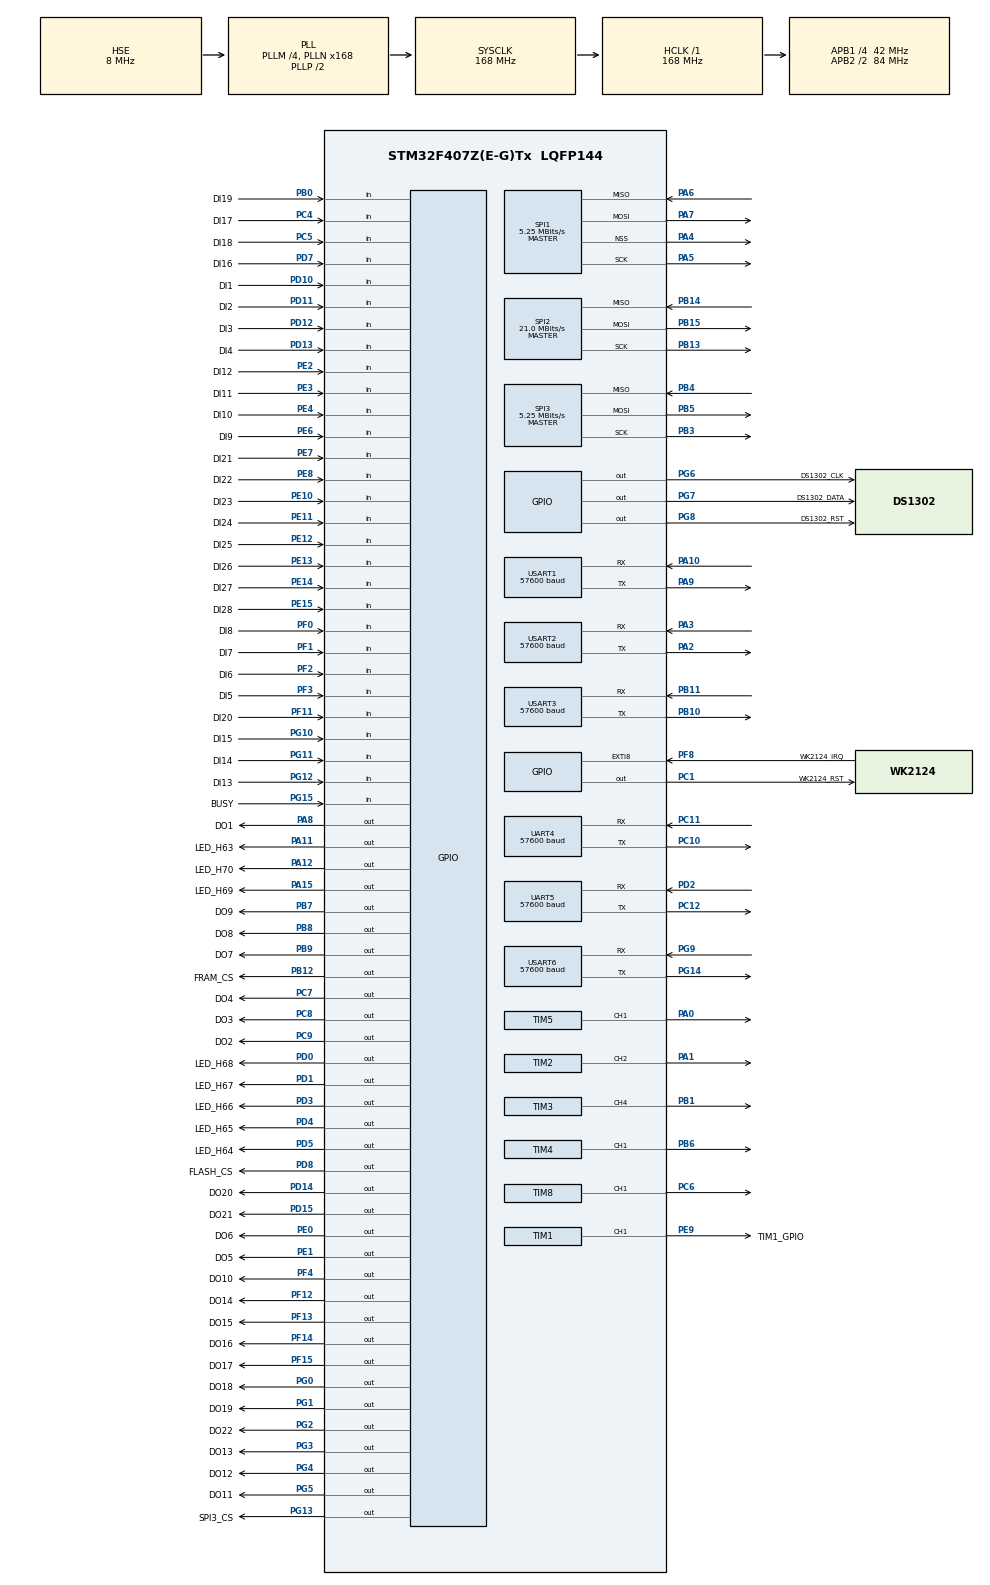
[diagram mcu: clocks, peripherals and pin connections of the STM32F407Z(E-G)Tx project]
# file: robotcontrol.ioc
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Mcu.Family=STM32F4
Mcu.Name=STM32F407Z(E-G)Tx
Mcu.Package=LQFP144
NVIC.EXTI9_5_IRQn=true\:0\:0\:false\:false\:true\:true\:true
NVIC.PriorityGroup=NVIC_PRIORITYGROUP_2
NVIC.TIM1_UP_TIM10_IRQn=true\:0\:0\:false\:false\:true\:true\:true
NVIC.TIM2_IRQn=true\:0\:0\:false\:false\:true\:true\:true
NVIC.TIM3_IRQn=true\:0\:0\:false\:false\:true\:true\:true
NVIC.TIM4_IRQn=true\:0\:0\:false\:false\:true\:true\:true
NVIC.TIM5_IRQn=true\:0\:0\:false\:false\:true\:true\:true
NVIC.TIM6_DAC_IRQn=true\:0\:0\:false\:false\:true\:true\:true
NVIC.TIM8_UP_TIM13_IRQn=true\:0\:0\:false\:false\:true\:true\:true
NVIC.UART4_IRQn=true\:0\:0\:false\:false\:true\:true\:true
NVIC.UART5_IRQn=true\:0\:0\:false\:false\:true\:true\:true
NVIC.USART1_IRQn=true\:0\:0\:false\:false\:true\:true\:true
NVIC.USART2_IRQn=true\:0\:0\:false\:false\:true\:true\:true
NVIC.USART3_IRQn=true\:0\:0\:false\:false\:true\:true\:true
NVIC.USART6_IRQn=true\:0\:0\:false\:false\:true\:true\:true
PA0-WKUP.Signal=S_TIM5_CH1
PA1.GPIO_PuPd=GPIO_PULLUP
PA1.GPIO_Speed=GPIO_SPEED_FREQ_MEDIUM
PA1.Signal=S_TIM2_CH2
PA10.GPIO_Speed=GPIO_SPEED_FREQ_MEDIUM
PA10.Mode=Asynchronous
PA10.Signal=USART1_RX
PA11.GPIO_Label=LED_H63
PA11.GPIO_PuPd=GPIO_PULLUP
PA11.PinState=GPIO_PIN_SET
PA11.Signal=GPIO_Output
PA12.GPIO_Label=LED_H70
PA12.GPIO_PuPd=GPIO_PULLUP
PA12.PinState=GPIO_PIN_SET
PA12.Signal=GPIO_Output
PA13.Mode=Serial_Wire
PA13.Signal=SYS_JTMS-SWDIO
PA14.Mode=Serial_Wire
PA14.Signal=SYS_JTCK-SWCLK
PA15.GPIO_Label=LED_H69
PA15.GPIO_PuPd=GPIO_PULLUP
PA15.PinState=GPIO_PIN_SET
PA15.Signal=GPIO_Output
PA2.GPIO_Speed=GPIO_SPEED_FREQ_MEDIUM
PA2.Mode=Asynchronous
PA2.Signal=USART2_TX
PA3.GPIO_Speed=GPIO_SPEED_FREQ_MEDIUM
PA3.Mode=Asynchronous
PA3.Signal=USART2_RX
PA4.Mode=NSS_Signal_Hard_Output
PA4.Signal=SPI1_NSS
PA5.Mode=Full_Duplex_Master
PA5.Signal=SPI1_SCK
PA6.Mode=Full_Duplex_Master
PA6.Signal=SPI1_MISO
PA7.Mode=Full_Duplex_Master
PA7.Signal=SPI1_MOSI
PA8.GPIO_Label=DO1
PA8.GPIO_PuPd=GPIO_PULLUP
PA8.GPIO_Speed=GPIO_SPEED_FREQ_LOW
PA8.PinState=GPIO_PIN_SET
PA8.Signal=GPIO_Output
PA9.GPIO_Speed=GPIO_SPEED_FREQ_MEDIUM
PA9.Mode=Asynchronous
PA9.Signal=USART1_TX
PB0.GPIO_Label=DI19
PB0.GPIO_PuPd=GPIO_PULLDOWN
PB0.Signal=GPIO_Input
PB1.GPIO_PuPd=GPIO_PULLUP
PB1.GPIO_Speed=GPIO_SPEED_FREQ_MEDIUM
PB1.Signal=S_TIM3_CH4
PB10.GPIO_Speed=GPIO_SPEED_FREQ_MEDIUM
PB10.Mode=Asynchronous
PB10.Signal=USART3_TX
PB11.GPIO_Speed=GPIO_SPEED_FREQ_MEDIUM
PB11.Mode=Asynchronous
PB11.Signal=USART3_RX
PB12.GPIO_Label=FRAM_CS
PB12.GPIO_PuPd=GPIO_PULLUP
PB12.GPIO_Speed=GPIO_SPEED_FREQ_HIGH
PB12.PinState=GPIO_PIN_SET
PB12.Signal=GPIO_Output
PB13.GPIO_Speed=GPIO_SPEED_FREQ_HIGH
PB13.Mode=Full_Duplex_Master
PB13.Signal=SPI2_SCK
PB14.GPIO_Speed=GPIO_SPEED_FREQ_HIGH
PB14.Mode=Full_Duplex_Master
PB14.Signal=SPI2_MISO
PB15.GPIO_Speed=GPIO_SPEED_FREQ_HIGH
PB15.Mode=Full_Duplex_Master
PB15.Signal=SPI2_MOSI
PB3.Mode=Full_Duplex_Master
PB3.Signal=SPI3_SCK
PB4.Mode=Full_Duplex_Master
PB4.Signal=SPI3_MISO
PB5.Mode=Full_Duplex_Master
PB5.Signal=SPI3_MOSI
PB6.GPIO_PuPd=GPIO_PULLUP
PB6.GPIO_Speed=GPIO_SPEED_FREQ_MEDIUM
PB6.Signal=S_TIM4_CH1
PB7.GPIO_Label=DO9
PB7.GPIO_PuPd=GPIO_PULLUP
PB7.PinState=GPIO_PIN_SET
PB7.Signal=GPIO_Output
PB8.GPIO_Label=DO8
PB8.GPIO_PuPd=GPIO_PULLUP
PB8.PinState=GPIO_PIN_SET
PB8.Signal=GPIO_Output
PB9.GPIO_Label=DO7
PB9.GPIO_PuPd=GPIO_PULLUP
PB9.PinState=GPIO_PIN_SET
PB9.Signal=GPIO_Output
PC1.GPIO_Label=WK2124_RST
PC1.GPIO_PuPd=GPIO_PULLUP
PC1.PinState=GPIO_PIN_SET
PC1.Signal=GPIO_Output
PC10.GPIO_Speed=GPIO_SPEED_FREQ_MEDIUM
PC10.Mode=Asynchronous
PC10.Signal=UART4_TX
PC11.GPIO_Speed=GPIO_SPEED_FREQ_MEDIUM
PC11.Mode=Asynchronous
PC11.Signal=UART4_RX
PC12.GPIO_Speed=GPIO_SPEED_FREQ_MEDIUM
PC12.Mode=Asynchronous
PC12.Signal=UART5_TX
PC14-OSC32_IN.Mode=LSE-External-Oscillator
PC14-OSC32_IN.Signal=RCC_OSC32_IN
PC15-OSC32_OUT.Mode=LSE-External-Oscillator
PC15-OSC32_OUT.Signal=RCC_OSC32_OUT
PC4.GPIO_Label=DI17
PC4.GPIO_PuPd=GPIO_PULLDOWN
PC4.Signal=GPIO_Input
PC5.GPIO_Label=DI18
PC5.GPIO_PuPd=GPIO_PULLDOWN
PC5.Signal=GPIO_Input
PC6.GPIO_PuPd=GPIO_PULLUP
PC6.GPIO_Speed=GPIO_SPEED_FREQ_MEDIUM
PC6.Signal=S_TIM8_CH1
PC7.GPIO_Label=DO4
PC7.GPIO_PuPd=GPIO_PULLUP
PC7.PinState=GPIO_PIN_SET
PC7.Signal=GPIO_Output
PC8.GPIO_Label=DO3
PC8.GPIO_PuPd=GPIO_PULLUP
PC8.PinState=GPIO_PIN_SET
PC8.Signal=GPIO_Output
PC9.GPIO_Label=DO2
PC9.GPIO_PuPd=GPIO_PULLUP
PC9.PinState=GPIO_PIN_SET
PC9.Signal=GPIO_Output
PD0.GPIO_Label=LED_H68
PD0.GPIO_PuPd=GPIO_PULLUP
PD0.PinState=GPIO_PIN_SET
PD0.Signal=GPIO_Output
PD1.GPIO_Label=LED_H67
PD1.GPIO_PuPd=GPIO_PULLUP
PD1.PinState=GPIO_PIN_SET
PD1.Signal=GPIO_Output
PD10.GPIO_Label=DI1
PD10.GPIO_PuPd=GPIO_PULLDOWN
PD10.Signal=GPIO_Input
PD11.GPIO_Label=DI2
PD11.GPIO_PuPd=GPIO_PULLDOWN
PD11.Signal=GPIO_Input
PD12.GPIO_Label=DI3
PD12.GPIO_PuPd=GPIO_PULLDOWN
PD12.Signal=GPIO_Input
PD13.GPIO_Label=DI4
PD13.GPIO_PuPd=GPIO_PULLDOWN
PD13.Signal=GPIO_Input
PD14.GPIO_Label=DO20
PD14.GPIO_PuPd=GPIO_PULLUP
PD14.PinState=GPIO_PIN_SET
PD14.Signal=GPIO_Output
PD15.GPIO_Label=DO21
PD15.GPIO_PuPd=GPIO_PULLUP
PD15.PinState=GPIO_PIN_SET
PD15.Signal=GPIO_Output
PD2.GPIO_Speed=GPIO_SPEED_FREQ_MEDIUM
PD2.Mode=Asynchronous
PD2.Signal=UART5_RX
PD3.GPIO_Label=LED_H66
PD3.GPIO_PuPd=GPIO_PULLUP
PD3.PinState=GPIO_PIN_SET
PD3.Signal=GPIO_Output
PD4.GPIO_Label=LED_H65
PD4.GPIO_PuPd=GPIO_PULLUP
PD4.PinState=GPIO_PIN_SET
PD4.Signal=GPIO_Output
PD5.GPIO_Label=LED_H64
PD5.GPIO_PuPd=GPIO_PULLUP
PD5.PinState=GPIO_PIN_SET
PD5.Signal=GPIO_Output
PD7.GPIO_Label=DI16
PD7.GPIO_PuPd=GPIO_PULLDOWN
PD7.Signal=GPIO_Input
PD8.GPIO_Label=FLASH_CS
PD8.GPIO_PuPd=GPIO_PULLUP
PD8.GPIO_Speed=GPIO_SPEED_FREQ_HIGH
PD8.PinState=GPIO_PIN_SET
PD8.Signal=GPIO_Output
PE0.GPIO_Label=DO6
PE0.GPIO_PuPd=GPIO_PULLUP
PE0.PinState=GPIO_PIN_SET
PE0.Signal=GPIO_Output
PE1.GPIO_Label=DO5
PE1.GPIO_PuPd=GPIO_PULLUP
PE1.GPIO_Speed=GPIO_SPEED_FREQ_LOW
PE1.PinState=GPIO_PIN_SET
PE1.Signal=GPIO_Output
PE10.GPIO_Label=DI23
PE10.GPIO_PuPd=GPIO_PULLDOWN
PE10.Signal=GPIO_Input
PE11.GPIO_Label=DI24
PE11.GPIO_PuPd=GPIO_PULLDOWN
PE11.Signal=GPIO_Input
PE12.GPIO_Label=DI25
PE12.GPIO_PuPd=GPIO_PULLDOWN
PE12.Signal=GPIO_Input
PE13.GPIO_Label=DI26
PE13.GPIO_PuPd=GPIO_PULLDOWN
PE13.Signal=GPIO_Input
PE14.GPIO_Label=DI27
PE14.GPIO_PuPd=GPIO_PULLDOWN
PE14.Signal=GPIO_Input
PE15.GPIO_Label=DI28
PE15.GPIO_PuPd=GPIO_PULLDOWN
PE15.Signal=GPIO_Input
PE2.GPIO_Label=DI12
PE2.GPIO_PuPd=GPIO_PULLDOWN
PE2.Signal=GPIO_Input
PE3.GPIO_Label=DI11
PE3.GPIO_PuPd=GPIO_PULLDOWN
PE3.Signal=GPIO_Input
PE4.GPIO_Label=DI10
PE4.GPIO_PuPd=GPIO_PULLDOWN
PE4.Signal=GPIO_Input
PE6.GPIO_Label=DI9
PE6.GPIO_PuPd=GPIO_PULLDOWN
PE6.Signal=GPIO_Input
PE7.GPIO_Label=DI21
PE7.GPIO_PuPd=GPIO_PULLDOWN
PE7.Signal=GPIO_Input
PE8.GPIO_Label=DI22
PE8.GPIO_PuPd=GPIO_PULLDOWN
PE8.Signal=GPIO_Input
PE9.GPIO_Label=TIM1_GPIO
PE9.GPIO_PuPd=GPIO_PULLUP
PE9.GPIO_Speed=GPIO_SPEED_FREQ_MEDIUM
PE9.Signal=S_TIM1_CH1
PF0.GPIO_Label=DI8
PF0.GPIO_PuPd=GPIO_PULLDOWN
PF0.Signal=GPIO_Input
PF1.GPIO_Label=DI7
PF1.GPIO_PuPd=GPIO_PULLDOWN
PF1.Signal=GPIO_Input
PF11.GPIO_Label=DI20
PF11.GPIO_PuPd=GPIO_PULLUP
PF11.Signal=GPIO_Input
PF12.GPIO_Label=DO14
PF12.GPIO_PuPd=GPIO_PULLUP
PF12.PinState=GPIO_PIN_SET
PF12.Signal=GPIO_Output
PF13.GPIO_Label=DO15
PF13.GPIO_PuPd=GPIO_PULLUP
PF13.PinState=GPIO_PIN_SET
PF13.Signal=GPIO_Output
PF14.GPIO_Label=DO16
PF14.GPIO_PuPd=GPIO_PULLUP
PF14.PinState=GPIO_PIN_SET
PF14.Signal=GPIO_Output
PF15.GPIO_Label=DO17
PF15.GPIO_PuPd=GPIO_PULLUP
PF15.PinState=GPIO_PIN_SET
PF15.Signal=GPIO_Output
PF2.GPIO_Label=DI6
PF2.GPIO_PuPd=GPIO_PULLDOWN
PF2.Signal=GPIO_Input
PF3.GPIO_Label=DI5
PF3.GPIO_PuPd=GPIO_PULLDOWN
PF3.Signal=GPIO_Input
PF4.GPIO_Label=DO10
PF4.GPIO_PuPd=GPIO_PULLUP
PF4.PinState=GPIO_PIN_SET
PF4.Signal=GPIO_Output
PF8.GPIO_Label=WK2124_IRQ
PF8.GPIO_ModeDefaultEXTI=GPIO_MODE_IT_FALLING
PF8.GPIO_PuPd=GPIO_PULLUP
PF8.Signal=GPXTI8
PG0.GPIO_Label=DO18
PG0.GPIO_PuPd=GPIO_PULLUP
PG0.PinState=GPIO_PIN_SET
PG0.Signal=GPIO_Output
PG1.GPIO_Label=DO19
PG1.GPIO_PuPd=GPIO_PULLUP
PG1.PinState=GPIO_PIN_SET
PG1.Signal=GPIO_Output
PG10.GPIO_Label=DI15
PG10.GPIO_PuPd=GPIO_PULLDOWN
PG10.Signal=GPIO_Input
PG11.GPIO_Label=DI14
PG11.GPIO_PuPd=GPIO_PULLDOWN
PG11.Signal=GPIO_Input
PG12.GPIO_Label=DI13
PG12.GPIO_PuPd=GPIO_PULLDOWN
PG12.Signal=GPIO_Input
PG13.GPIO_Label=SPI3_CS
PG13.GPIO_PuPd=GPIO_PULLUP
PG13.GPIO_Speed=GPIO_SPEED_FREQ_HIGH
PG13.PinState=GPIO_PIN_SET
PG13.Signal=GPIO_Output
PG14.GPIO_Speed=GPIO_SPEED_FREQ_MEDIUM
PG14.Mode=Asynchronous
PG14.Signal=USART6_TX
PG15.GPIO_Label=BUSY
PG15.GPIO_PuPd=GPIO_PULLDOWN
PG15.Signal=GPIO_Input
PG2.GPIO_Label=DO22
PG2.GPIO_PuPd=GPIO_PULLUP
PG2.PinState=GPIO_PIN_SET
PG2.Signal=GPIO_Output
PG3.GPIO_Label=DO13
PG3.GPIO_PuPd=GPIO_PULLUP
PG3.PinState=GPIO_PIN_SET
PG3.Signal=GPIO_Output
PG4.GPIO_Label=DO12
PG4.GPIO_PuPd=GPIO_PULLUP
PG4.PinState=GPIO_PIN_SET
PG4.Signal=GPIO_Output
PG5.GPIO_Label=DO11
PG5.GPIO_PuPd=GPIO_PULLUP
PG5.PinState=GPIO_PIN_SET
PG5.Signal=GPIO_Output
PG6.GPIO_Label=DS1302_CLK
PG6.Signal=GPIO_Output
PG7.GPIO_Label=DS1302_DATA
PG7.GPIO_ModeDefaultOutputPP=GPIO_MODE_OUTPUT_OD
PG7.Signal=GPIO_Output
PG8.GPIO_Label=DS1302_RST
PG8.Signal=GPIO_Output
PG9.GPIO_Speed=GPIO_SPEED_FREQ_MEDIUM
PG9.Mode=Asynchronous
PG9.Signal=USART6_RX
PH0-OSC_IN.Mode=HSE-External-Oscillator
PH0-OSC_IN.Signal=RCC_OSC_IN
PH1-OSC_OUT.Mode=HSE-External-Oscillator
PH1-OSC_OUT.Signal=RCC_OSC_OUT
ProjectManager.HeapSize=0x200
ProjectManager.StackSize=0x400
ProjectManager.TargetToolchain=MDK-ARM V5.27
RCC.48MHZClocksFreq_Value=84000000
RCC.AHBFreq_Value=168000000
RCC.APB1CLKDivider=RCC_HCLK_DIV4
RCC.APB1Freq_Value=42000000
RCC.APB1TimFreq_Value=84000000
RCC.APB2CLKDivider=RCC_HCLK_DIV2
RCC.APB2Freq_Value=84000000
RCC.APB2TimFreq_Value=168000000
RCC.CortexFreq_Value=168000000
RCC.HCLKFreq_Value=168000000
RCC.HSE_VALUE=8000000
RCC.HSI_VALUE=16000000
RCC.PLLM=4
RCC.PLLN=168
RCC.PLLSourceVirtual=RCC_PLLSOURCE_HSE
RCC.SYSCLKFreq_VALUE=168000000
RCC.SYSCLKSource=RCC_SYSCLKSOURCE_PLLCLK
RCC.VCOOutputFreq_Value=336000000
SH.S_TIM1_CH1.0=TIM1_CH1,PWM Generation1 CH1
SH.S_TIM2_CH2.0=TIM2_CH2,PWM Generation2 CH2
SH.S_TIM3_CH4.0=TIM3_CH4,PWM Generation4 CH4
SH.S_TIM4_CH1.0=TIM4_CH1,PWM Generation1 CH1
SH.S_TIM5_CH1.0=TIM5_CH1,PWM Generation1 CH1
SH.S_TIM8_CH1.0=TIM8_CH1,PWM Generation1 CH1
SPI1.BaudRatePrescaler=SPI_BAUDRATEPRESCALER_16
SPI1.CalculateBaudRate=5.25 MBits/s
SPI1.Direction=SPI_DIRECTION_2LINES
SPI1.Mode=SPI_MODE_MASTER
SPI1.VirtualNSS=VM_NSSHARD
SPI1.VirtualType=VM_MASTER
SPI2.BaudRatePrescaler=SPI_BAUDRATEPRESCALER_2
SPI2.CalculateBaudRate=21.0 MBits/s
SPI2.Direction=SPI_DIRECTION_2LINES
SPI2.Mode=SPI_MODE_MASTER
SPI2.VirtualType=VM_MASTER
SPI3.BaudRatePrescaler=SPI_BAUDRATEPRESCALER_8
SPI3.CalculateBaudRate=5.25 MBits/s
SPI3.Direction=SPI_DIRECTION_2LINES
SPI3.Mode=SPI_MODE_MASTER
SPI3.VirtualType=VM_MASTER
TIM1.AutoReloadPreload=TIM_AUTORELOAD_PRELOAD_ENABLE
TIM1.Channel-PWM\ Generation1\ CH1=TIM_CHANNEL_1
TIM1.OCMode_PWM-PWM\ Generation1\ CH1=TIM_OCMODE_PWM2
TIM1.OCPolarity_1=TIM_OCPOLARITY_LOW
TIM1.Period=1000-1
TIM1.Prescaler=167
TIM1.TIM_MasterOutputTrigger=TIM_TRGO_UPDATE
TIM2.Channel-PWM\ Generation2\ CH2=TIM_CHANNEL_2
TIM2.OCMode_PWM-PWM\ Generation2\ CH2=TIM_OCMODE_PWM2
TIM2.OCPolarity_2=TIM_OCPOLARITY_LOW
TIM2.Period=1000-1
TIM2.Prescaler=84-1
TIM3.Channel-PWM\ Generation4\ CH4=TIM_CHANNEL_4
TIM3.OCMode_PWM-PWM\ Generation4\ CH4=TIM_OCMODE_PWM2
TIM3.OCPolarity_4=TIM_OCPOLARITY_LOW
TIM3.Period=1000-1
TIM3.Prescaler=84-1
TIM4.Channel-PWM\ Generation1\ CH1=TIM_CHANNEL_1
TIM4.OCMode_PWM-PWM\ Generation1\ CH1=TIM_OCMODE_PWM2
TIM4.OCPolarity_1=TIM_OCPOLARITY_LOW
TIM4.Period=1000-1
TIM4.Prescaler=84-1
TIM5.Channel-PWM\ Generation1\ CH1=TIM_CHANNEL_1
TIM5.OCMode_PWM-PWM\ Generation1\ CH1=TIM_OCMODE_PWM2
TIM5.OCPolarity_1=TIM_OCPOLARITY_LOW
TIM5.Period=1000-1
TIM5.Prescaler=84-1
TIM6.AutoReloadPreload=TIM_AUTORELOAD_PRELOAD_ENABLE
TIM6.Period=1000
TIM6.Prescaler=84-1
TIM7.Period=1
TIM7.Prescaler=84-1
TIM8.Channel-PWM\ Generation1\ CH1=TIM_CHANNEL_1
TIM8.OCMode_PWM-PWM\ Generation1\ CH1=TIM_OCMODE_PWM2
TIM8.OCPolarity_1=TIM_OCPOLARITY_LOW
TIM8.Period=1000-1
TIM8.Prescaler=168-1
UART4.BaudRate=57600
UART4.VirtualMode=Asynchronous
UART5.BaudRate=57600
UART5.VirtualMode=Asynchronous
USART1.BaudRate=57600
USART1.VirtualMode=VM_ASYNC
USART2.BaudRate=57600
USART2.VirtualMode=VM_ASYNC
USART3.BaudRate=57600
USART3.VirtualMode=VM_ASYNC
USART6.BaudRate=57600
USART6.VirtualMode=VM_ASYNC
VP_TIM1_VS_ClockSourceINT.Mode=Internal
VP_TIM2_VS_ClockSourceINT.Mode=Internal
VP_TIM3_VS_ClockSourceINT.Mode=Internal
VP_TIM4_VS_ClockSourceINT.Mode=Internal
VP_TIM5_VS_ClockSourceINT.Mode=Internal
VP_TIM6_VS_ClockSourceINT.Mode=Enable_Timer
VP_TIM7_VS_ClockSourceINT.Mode=Enable_Timer
VP_TIM8_VS_ClockSourceINT.Mode=Internal
board=custom

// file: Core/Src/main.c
/* USER CODE BEGIN Header */
/**
  ******************************************************************************
  * @file           : main.c
  * @brief          : Main program body
  ******************************************************************************
  * @attention
  *
  * <h2><center>&copy; Copyright (c) 2021 QINGDAO SANLI.
  * All rights reserved.</center></h2>
  *
  * This software component is licensed by ST under BSD 3-Clause license,
  * the "License"; You may not use this file except in compliance with the
  * License. You may obtain a copy of the License at:
  *                        opensource.org/licenses/BSD-3-Clause
  *
  ******************************************************************************
  */
/* USER CODE END Header */
#include "main.h"
#include "spi.h"
#include "tim.h"
#include "usart.h"
#include "gpio.h"

/* USER CODE BEGIN Includes */
// #include "stdio.h"
#include "stddef.h"
#include <stdlib.h>
#include <math.h>
#include "ecm_define.h"
#include "GlobalConst.h"
#include "GlobalV.h"
#include "GlobalV_Extern.h" // 全局变量声明
#include "typedef.h"
#include "wk2xxx.h"
#include "w25qxx.h"
#include "bsp_MOTOR3.h"
#include "bsp_MOTOR1.h"
#include "bsp_MOTOR2.h"
#include "bsp_MOTOR4.h"
#include "bsp_MOTOR5.h"
#include "bsp_MOTOR6.h"
#include "Macro.h"
#include "global_varial.h"
#include "Dowith.h"

/* USER CODE END Includes */

/* USER CODE BEGIN PM */
#ifdef GNUC
#define PUTCHAR_PROTOTYPE int __io_putchar(int ch)
#define GETCHAR_PROTOTYPE int __io_getchar(void)
#else
#define PUTCHAR_PROTOTYPE int fputc(int ch, FILE *f)
#define GETCHAR_PROTOTYPE int fgetc(FILE *f)
#endif /* GNUC */
/* USER CODE END PM */

/* USER CODE BEGIN PV */
//uint8_t			bNetworkMap[42] = {DRIVE,DRIVE,DRIVE,DRIVE,DRIVE,DRIVE,DRIVE,DRIVE};
uint8_t bNetworkMap[42] = {DRIVE, None, None, None, None, None, None, None};
char printbuf[128];
int GPIO_test(void);

#define NUM 1000
uint32_t send_Buf[NUM] = {0};

/* USER CODE END PV */

void SystemClock_Config(void);
/* USER CODE BEGIN PFP */
static int startflag = 0;
int32_t targetp;

int32_t current_Pos;
int32_t current_Pos2;
// uint16_t Master_CMD;
// uint16_t Master_state;
// uint16_t current_state;
int32_t distance; //运行距离
uint8_t dir = 0;  //方向
uint16_t asc;	  //加速计数

extern uint32_t IO_Input;

struct rbuff_st
{
	uint16_t CMD;
	uint16_t Parm;
	int32_t Data1;
	int32_t Data2;
}; /* Receive Buffer */
extern struct rbuff_st rbuff[];

//要写入到W25Q16的字符串数组
const u8 TEXT_Buffer[] = {"Explorer STM32F4 SPI TEST"};
#define SIZE sizeof(TEXT_Buffer)

int main_ini(void);

/* USER CODE END PFP */

/* USER CODE BEGIN 0 */
//重定向printf和scanf：修改fgetc和fputc
PUTCHAR_PROTOTYPE
{
	HAL_UART_Transmit(&huart3, (uint8_t *)&ch, 1, HAL_MAX_DELAY);
	return ch;
}

GETCHAR_PROTOTYPE
{
	int ch;
	HAL_UART_Receive(&huart3, (uint8_t *)&ch, 1, HAL_MAX_DELAY);
	return ch;
}

/* USER CODE END 0 */

int main(void)
{
	/* USER CODE BEGIN 1 */
	u32 cyc_counter = 0;
	/* USER CODE END 1 */

	/* MCU Configuration--------------------------------------------------------*/

	/* Reset of all peripherals, Initializes the Flash interface and the Systick. */
	HAL_Init();

	/* Configure the system clock */
	SystemClock_Config();

	/* USER CODE BEGIN SysInit */
	HAL_Delay(1000); //延时
	/* USER CODE END SysInit */

	/* Initialize all configured peripherals */
	MX_GPIO_Init();
	MX_SPI1_Init();
	MX_SPI2_Init();
	MX_SPI3_Init();
	MX_TIM1_Init();
	MX_TIM2_Init();
	MX_TIM3_Init();
	MX_TIM4_Init();
	MX_TIM5_Init();
	MX_TIM8_Init();
	MX_UART4_Init();
	MX_UART5_Init();
	MX_USART1_UART_Init();
	MX_USART2_UART_Init();
	MX_USART3_UART_Init();
	MX_USART6_UART_Init();
	MX_TIM7_Init();
	MX_TIM6_Init();
	/* USER CODE BEGIN 2 */
	InitClock();		  // 初始化外部时钟DS1302
	Init_WK_Uart();		  //初始化WK2124扩展串口
	Initial_PWM_Motors(); //初始化电机的PWM
	// Test_EEPROM();		  //测试EEPROM

	//EtherCAT初始化
	// Init_EtherCAT();
	//	main_ini();

	ParLst_Init();	 // RAM中设定参数表列初始化，FLASH——>RAM
	Boot_ParLst();	 // 初始化STM32设定参数
	Variable_Init(); // Initialize VARIABLE
	ParLimit();		 // 参数限制

	Send_Driver_CMD(Pw_EquipmentNo3, 06, 0x8910, 0); //写驱动器3的P8910参数=0，RDY状态
	Send_Driver_CMD(Pw_EquipmentNo3, 06, 0x0029, 1); //写驱动器3的P0029参数=1，使用外部制动电阻
	Send_StopCMD();
	/* USER CODE END 2 */

	/* Infinite loop */
	/* USER CODE BEGIN WHILE */
	while (1)
	{
		Boot_ParLst();			   //初始化设定参数，命令：Pw_ModPar = 2000，Pw_ParInitial = 4321
		PosCMD_SaveTo_exFLASH();   //将RAM中的位置命令到外部FLASH和FRAM，命令：Pw_ModPar == 2000，Pw_ParInitial == 8000
		PosCMD_ReadFrom_exFLASH(); //从外部FLASH按组号读取位置命令到RAM和FRAM，命令：Pw_ModPar = 2000，Pw_ParInitial = 4000
		ParLst_Init_Group2Zero();  //清零位置命令，命令：Pw_ModPar == 2000 && Pw_ParInitial == 9876
		ParLst_Init_Pos2Zero();	   //清零位置，命令：Pw_ModPar == 2000 && Pw_ParInitial == 5432
		Pos_Manual_Adj();		   //手动调整编码器位置
		ParLimit();				   // 参数限制
								   //		ReadWriteRealTime(); // 读写实时时钟 ISL1208

		EquipStatus();	  // 设备状态
		KglStatus();	  // 开关量状态
		DigitalIn();	  // DI
		Manual_Control(); // 手动控制启停

		SavePar_Prompt();	 // 定时保存设定参数到FLASH"+"状态提示
		ForceTime_SavePar(); // 定时强制保存参数

		Time_Output(); // 软件时钟输出

		UART_TX(); //串口通讯

		Driver_Control();	  //电机运行控制
		Reset_Drivers();	  //有复位命令，则复位到原点
		BRAKE_Control();	  //刹车控制
		is_Reseted();		  //判断是否在原点
		Cal_Pos_Speed();	  //计算脉冲值和速度
		Record_Current_Pos(); //记录当前位置
		Control_Hand();		  //机械手控制
		//  Limit_Max_Pos();	  //限制最大最小位置范围
		// IWDG_Feed();								// 喂狗	2013.7.3

		cyc_counter++;
		Pr_cyclecounter_show = cyc_counter & 0x0000FFFF;
		Pr_cyclecounter_HW = (cyc_counter & 0xFFFF0000) >> 16;
		TEST_Send_Pwm();
		// Rd2Wr_IO();

		/* USER CODE END WHILE */

	}
}

void SystemClock_Config(void)
{
	RCC_OscInitTypeDef RCC_OscInitStruct = {0};
	RCC_ClkInitTypeDef RCC_ClkInitStruct = {0};

	/** Configure the main internal regulator output voltage
  */
	__HAL_RCC_PWR_CLK_ENABLE();
	__HAL_PWR_VOLTAGESCALING_CONFIG(PWR_REGULATOR_VOLTAGE_SCALE1);
	/** Initializes the RCC Oscillators according to the specified parameters
  * in the RCC_OscInitTypeDef structure.
  */
	RCC_OscInitStruct.OscillatorType = RCC_OSCILLATORTYPE_HSE;
	RCC_OscInitStruct.HSEState = RCC_HSE_ON;
	RCC_OscInitStruct.PLL.PLLState = RCC_PLL_ON;
	RCC_OscInitStruct.PLL.PLLSource = RCC_PLLSOURCE_HSE;
	RCC_OscInitStruct.PLL.PLLM = 4;
	RCC_OscInitStruct.PLL.PLLN = 168;
	RCC_OscInitStruct.PLL.PLLP = RCC_PLLP_DIV2;
	RCC_OscInitStruct.PLL.PLLQ = 4;
	if (HAL_RCC_OscConfig(&RCC_OscInitStruct) != HAL_OK)
	{
		Error_Handler();
	}
	/** Initializes the CPU, AHB and APB buses clocks
  */
	RCC_ClkInitStruct.ClockType = RCC_CLOCKTYPE_HCLK | RCC_CLOCKTYPE_SYSCLK | RCC_CLOCKTYPE_PCLK1 | RCC_CLOCKTYPE_PCLK2;
	RCC_ClkInitStruct.SYSCLKSource = RCC_SYSCLKSOURCE_PLLCLK;
	RCC_ClkInitStruct.AHBCLKDivider = RCC_SYSCLK_DIV1;
	RCC_ClkInitStruct.APB1CLKDivider = RCC_HCLK_DIV4;
	RCC_ClkInitStruct.APB2CLKDivider = RCC_HCLK_DIV2;

	if (HAL_RCC_ClockConfig(&RCC_ClkInitStruct, FLASH_LATENCY_5) != HAL_OK)
	{
		Error_Handler();
	}
}

/* USER CODE BEGIN 4 */
//延时1us
void PowerDelay(uint16_t nCount) //2015.9.12
{
	unsigned int i = 36;
	while (nCount--)
	{
		while (i > 0)
			i--;
		i = 36;
	}
}

void HAL_SYSTICK_Callback(void)
{
	static uint8_t time = 0;
	static uint32_t kk = 0;
	if (startflag)
	{
		//		targetp+=1000;

		time++;
		if (time > 0)
		{
			if ((rbuff[0].CMD & 0x00FF) == 0x00BF && (rbuff[0].Parm & 0x00FF) == 0x0008) //&&(rbuff[1].Parm&0xFF00)==0x0600
			{
				for (kk = 0; kk < 100; kk++)
				{
					//					tmp1=rbuff[1].Data1+80;
					if (dir == 1) //如果正方向，则位置加
					{
						if (distance < 10) //进行加减速设置
							asc += 2;
						else if (distance > 40)
							asc -= 2;
						if (asc > 2000)
							asc = 2000;
						else if (asc <= 200)
							asc = 200;
						targetp += asc;
					}
					else //如果逆方向，则位置减
					{
						if (distance > 40)
							asc += 2;
						else if (distance < 10)
							asc -= 2;
						if (asc > 2000)
							asc = 2000;
						else if (asc <= 200)
							asc = 200;
						targetp -= asc;
					}

					if (abs(targetp) > 10)
					{
						CMD15_CSP(1, targetp);
						SPI_exchange_polling();
						//						printf("current_Pos1= =%x\n\r", tmp1);
					}
					else
					{
						CMD00_ALL_GET_STATUS();
						SPI_exchange_polling();
						//						printf("current_Pos0= =%x\n\r", rbuff[1].Data1);
					}

					if ((rbuff[0].Data2 & 0xFF) < 20)
					{
						PowerDelay(20000);
					}
				}

				if (dir == 1)
					distance++;
				else
					distance--;
				if (distance >= 50 && dir == 1)
				{
					dir = 0;
					asc = 200;
					printf("current_Pos1(Real)= =%x\n\r", rbuff[1].Data1);
					printf("current_Pos1(targetp)= =%x\n\r", targetp);
				}
				else if (distance <= 0 && dir == 0)
				{
					dir = 1;
					asc = 200;
					printf("current_Pos2(Real)= =%x\n\r", rbuff[1].Data1);
					printf("current_Pos2(targetp)= =%x\n\r", targetp);
				}
			}
			else
			{
				CMD00_ALL_GET_STATUS();
				SPI_exchange_polling();
				//				printf("current_Pos0= =%x\n\r", rbuff[1].Data1);
			}
			time = 0;
		}
	}
}

void HAL_GPIO_EXTI_Callback(uint16_t GPIO_Pin)
{
	u8 gifr;

	switch (GPIO_Pin)
	{
	case GPIO_PIN_8:
		gifr = Wk2xxxReadReg(WK2XXX_PORT1, WK2XXX_GIFR); /**/
		if (gifr & WK2XXX_UT1INT)						 //判断子串口1是否有中断
		{
			/*数据接收*/
			WK_Rcv1Counter = wk_RxChars(WK2XXX_PORT1, WK_Rcv1Buffer); //一次接收的数据不会超过256Byte
			C_WK_NoRcv1Count = 0;
		}

		gifr = Wk2xxxReadReg(WK2XXX_PORT2, WK2XXX_GIFR); /**/
		if (gifr & WK2XXX_UT2INT)						 //判断子串口1是否有中断
		{
			/*数据接收*/
			WK_Rcv2Counter = wk_RxChars(WK2XXX_PORT2, WK_Rcv2Buffer); //一次接收的数据不会超过256Byte
			C_WK_NoRcv2Count = 0;
		}

		gifr = Wk2xxxReadReg(WK2XXX_PORT3, WK2XXX_GIFR); /**/
		if (gifr & WK2XXX_UT3INT)						 //判断子串口1是否有中断
		{
			/*数据接收*/
			WK_Rcv3Counter = wk_RxChars(WK2XXX_PORT3, WK_Rcv3Buffer); //一次接收的数据不会超过256Byte
			C_WK_NoRcv3Count = 0;
		}

		gifr = Wk2xxxReadReg(WK2XXX_PORT4, WK2XXX_GIFR); /**/
		if (gifr & WK2XXX_UT4INT)						 //判断子串口1是否有中断
		{
			/*数据接收*/
			WK_Rcv4Counter = wk_RxChars(WK2XXX_PORT4, WK_Rcv4Buffer); //一次接收的数据不会超过256Byte
			C_WK_NoRcv4Count = 0;
		}
		break;

	default:
		break;
	}
}

//接收中断回调函数
void HAL_UART_RxCpltCallback(UART_HandleTypeDef *huart)
{
	if (huart->Instance == USART1)
	{
		C_NoRcv1Count = 0;
		if (Rcv1Counter < RCV1_MAX - 2)
		{
			Rcv1Buffer[Rcv1Counter++] = Tmp_Rxd1Buffer;
		}
		//再次开启接收
		HAL_UART_Receive_IT(&huart1, (uint8_t *)&Tmp_Rxd1Buffer, 1);
	}
	else if (huart->Instance == USART2)
	{
		C_NoRcv2Count = 0;
		if (Rcv2Counter < RCV2_MAX - 2)
		{
			Rcv2Buffer[Rcv2Counter++] = Tmp_Rxd2Buffer;
		}
		//再次开启接收
		HAL_UART_Receive_IT(&huart2, (uint8_t *)&Tmp_Rxd2Buffer, 1);
	}
	else if (huart->Instance == USART3)
	{
		C_NoRcv3Count = 0;
		if (Rcv3Counter < RCV3_MAX - 2)
		{
			Rcv3Buffer[Rcv3Counter++] = Tmp_Rxd3Buffer;
		}
		//再次开启接收
		HAL_UART_Receive_IT(&huart3, (uint8_t *)&Tmp_Rxd3Buffer, 1);
	}
	else if (huart->Instance == UART4)
	{
		C_NoRcv4Count = 0;
		if (Rcv4Counter < RCV4_MAX - 2)
		{
			Rcv4Buffer[Rcv4Counter++] = Tmp_Rxd4Buffer;
		}
		//再次开启接收
		HAL_UART_Receive_IT(&huart4, (uint8_t *)&Tmp_Rxd4Buffer, 1);
	}
	else if (huart->Instance == UART5)
	{
		C_NoRcv5Count = 0;
		if (Rcv5Counter < RCV5_MAX - 2)
		{
			Rcv5Buffer[Rcv5Counter++] = Tmp_Rxd5Buffer;
		}
		//再次开启接收
		HAL_UART_Receive_IT(&huart5, (uint8_t *)&Tmp_Rxd5Buffer, 1);
	}
	else if (huart->Instance == USART6)
	{
		C_NoRcv6Count = 0;
		if (Rcv6Counter < RCV6_MAX - 2)
		{
			Rcv6Buffer[Rcv6Counter++] = Tmp_Rxd6Buffer;
		}
		//再次开启接收
		HAL_UART_Receive_IT(&huart6, (uint8_t *)&Tmp_Rxd6Buffer, 1);
	}
}

//测试EEPROM-W25Q16
void Test_EEPROM(void)
{
	//wk2xxx相关定义
	// uint8_t gena;
	u8 datatemp[SIZE];
	u32 FLASH_SIZE;
	u8 i;
	// u16 j;
	uint8_t read_buf[10] = {0};
	uint8_t write_buf[10] = {0};
	uint32_t device_id;
	B_SelCS = CS_Flash1;

	W25qxx_Init();

	while ((W25qxx_ReadID() & 0x0000FFFF) != _W25Q16) //检测不到W25Q16
	{
		printf("W25Q16 Check Failed!");
		delay_ms(500);
		printf("Please Check!      ");
		delay_ms(500);
	}

	printf("W25Q16 Ready!\r\n");
	FLASH_SIZE = 2 * 1024 * 1024; //W25Q16，容量2MB
	printf("Start Write W25Q16....——1\r\n");
	SPI_FLASH_BufferWrite((u8 *)TEXT_Buffer, FLASH_SIZE - 100, SIZE); //从倒数第100个地址处开始,写入SIZE长度的数据
	printf("W25Q16 Write Finished!——1\r\n");						  //提示传送完成

	printf("Start Write W25Q16....——2\r\n");
	W25QXX_Write_WithErase((u8 *)TEXT_Buffer, 5, SIZE);
	printf("W25Q16 Write Finished!——2\r\n"); //提示传送完成

	printf("Start Read W25Q16.... \r\n");
	W25qxx_ReadBytes(datatemp, 5, SIZE);  //从倒数第100个地址处开始,读出SIZE个字节
	printf("The Data Readed Is:   \r\n"); //提示传送完成
	for (i = 0; i < sizeof(datatemp); i++)
		printf(" %d \r\n", datatemp[i]); //显示读到的字符串

	//另外一段测试读写W25Q16的程序
	printf("W25Q64 SPI Flash Test By YLS\r\n");
	device_id = W25qxx_ReadID();
	printf("W25Q16 Device ID is 0x%04x\r\n", device_id);

	/* 为了验证，首先读取要写入地址处的数据 */
	printf("-------- read data before write -----------\r\n");
	W25qxx_ReadBytes(read_buf, 0, 10);

	for (i = 0; i < 10; i++)
	{
		printf("[0x%08x]:0x%02x\r\n", i, *(read_buf + i));
	}

	/* 擦除该扇区 */
	printf("-------- erase sector 0 -----------\r\n");
	W25qxx_EraseSector(0);

	/* 再次读数据 */
	printf("-------- read data after erase -----------\r\n");
	W25qxx_ReadBytes(read_buf, 0, 10);
	for (i = 0; i < 10; i++)
	{
		printf("[0x%08x]:0x%02x\r\n", i, *(read_buf + i));
	}

	/* 写数据 */
	printf("-------- write data -----------\r\n");
	for (i = 0; i < 10; i++)
	{
		write_buf[i] = i;
	}
	W25qxx_WriteBytes_Page(write_buf, 0, 10);

	/* 再次读数据 */
	printf("-------- read data after write -----------\r\n");
	W25qxx_ReadBytes(read_buf, 0, 10);
	for (i = 0; i < 10; i++)
	{
		printf("[0x%08x]:0x%02x\r\n", i, *(read_buf + i));
	}
	printf("-------- read data end! -----------\r\n");

	/* 写FRAM数据 */
	printf("-------- write data to FRAM start-----------\r\n");
	// B_SelCS = CS_FMRAM1;
	SPI_FMRAM_BufferWrite((u8 *)TEXT_Buffer, 0, 10);
	printf("-------- write data to FRAM end-----------\r\n");

	/* 读FRAM数据 */
	printf("-------- read data from FRAM start-----------\r\n");
	SPI_FMRAM_BufferRead(read_buf, 0, 10);
	for (i = 0; i < 10; i++)
	{
		printf("[0x%08x]:0x%02x\r\n", i, *(read_buf + i));
	}
	printf("-------- read data from FRAM end-----------\r\n");
}

//初始化扩展串口
void Init_WK_Uart(void)
{
	unsigned char gena;
	//    WK2XXX_RST_Init();
	WK2XXX_SPI_Init();
	//	WK2XXX_Reset_Init();
	Wk2xxxInit(WK2XXX_PORT1);
	Wk2xxxInit(WK2XXX_PORT2);
	Wk2xxxInit(WK2XXX_PORT3);
	Wk2xxxInit(WK2XXX_PORT4);
	Wk2xxxSetBaud(WK2XXX_PORT1, B57600);
	Wk2xxxSetBaud(WK2XXX_PORT2, B57600);
	Wk2xxxSetBaud(WK2XXX_PORT3, B57600);
	Wk2xxxSetBaud(WK2XXX_PORT4, B57600);
	////	调试程序时，通过读GENA寄存器的值，判断主接口通信是否正常，未初始化，默认值读出来为0x30，正常0x3F
	gena = Wk2xxxReadReg(WK2XXX_GPORT, WK2XXX_GENA);
	printf("gena=%x\n", gena);
}

//初始化EtherCAT
void Init_EtherCAT(void)
{
	int i;
	/*模式配置*/
	SPI_ECAT_CS_OFF; //SPI-CS片选

	do
	{
		printf("Set to Pre OP\n");
		CMD01_SET_STATE(STATE_PRE_OP); //将所有从站设置进入PRE_OP状态
		SPI_exchange_polling();
		HAL_Delay(1000);
		CMD02_SET_AXIS(0, (uint8_t *)bNetworkMap); //设定从站类型，配置第一个从站为DRIVE子站
		SPI_exchange_polling();
		HAL_Delay(1000);
		CMD06_DRIVE_MODE(1, CSP_MODE, 1);
		SPI_exchange_polling();
		HAL_Delay(1000);			//yan chi da yi xie
		CMD03_SET_DC(8000, 0xffff); //设定周期数据250us ,必须是250us整数倍
		SPI_exchange_polling();
		HAL_Delay(200);

		CMD00_ALL_GET_STATUS();
		SPI_exchange_polling();
		HAL_Delay(100);

		printf("Set to OP\n");
		CMD01_SET_STATE(STATE_OPERATIONAL); //OP状态
		SPI_exchange_polling();
		HAL_Delay(1000);
		printf("0 rbuff[0].CMD=%d  ", rbuff[0].CMD);
		printf("0 rbuff[0].Parm=%d  \n", rbuff[0].Parm);
	} while ((((rbuff[0].CMD & 0x00FF) != 0x00BF) && ((rbuff[0].Parm & 0x00FF) != 0x0008)));
	printf("rbuff[0].CMD=%d  ", rbuff[0].CMD);
	printf("rbuff[0].Parm=%d  ", rbuff[0].Parm);
	printf("In OP Status\n");

	while (1)
	{
		CMD00_ALL_GET_STATUS();
		SPI_exchange_polling();
		HAL_Delay(100);

		if (((rbuff[0].CMD & 0x00FF) == 0x00BF) && ((rbuff[0].Parm & 0x00FF) == 0x0008))
		{
			i++;
		}
		else
		{
			i = 0;
		}
		printf("rbuff[0].CMD=%d  ", rbuff[0].CMD);
		printf("rbuff[0].Parm=%d  ", rbuff[0].Parm);

		printf("Now is OP Status,%d  \n", i);
		if (i >= 100)
		{
			break;
		}
	}

	CMD11_SVON(1);
	SPI_exchange_polling();
	HAL_Delay(1000);
	//	while(abs(rbuff[1].Data1)<=1000)	//(rbuff[0].CMD&0x00FF)!=0x00BF &&(rbuff[0].Parm&0x00FF)!=0x0008 &&
	//	{
	//		CMD00_ALL_GET_STATUS();
	//		SPI_exchange_polling();
	////		HAL_Delay(1000);
	//	}
	targetp = rbuff[1].Data1;
	startflag = 1;
	dir = 1;
	distance = 0;
}

void UART_TX(void)
{
	Com1_RcvProcess(); // 串口1接收处理
	Com1_SlaveSend();  // 串口1从机发送

	Com2_RcvProcess(); // 串口2接收处理
	Com2_SlaveSend();  // 串口2从机发送

	Com3_RcvProcess(); // 串口3接收处理
	Com3_SlaveSend();  // 串口3从机发送

	Com4_RcvProcess(); // 串口4接收处理
	Com4_SlaveSend();  // 串口4从机发送

	Com5_RcvProcess(); // 串口5接收处理
	Com5_SlaveSend();  // 串口5从机发送

	Com6_RcvProcess(); // 串口6接收处理
	Com6_SlaveSend();  // 串口6从机发送

	WK_Com1_RcvProcess(); //WK2124扩展串口1接收处理
	WK_Com1_SlaveSend();  //WK2124扩展串口1发送处理

	WK_Com2_RcvProcess();
	WK_Com2_SlaveSend();

	WK_Com3_RcvProcess();
	WK_Com3_SlaveSend();

	WK_Com4_RcvProcess();
	WK_Com4_SlaveSend();
}

//测试发PWM波
void TEST_Send_Pwm(void)
{
	if (!Old_K_SecondPonit)
	{
		if (K_SecondPonit || Pw_Driver1_Enable) //注意： 闭合时，运行。断开时，停止运行。
		{
			Pw_Driver1_Enable = 0;
			//停止后才能继续发送
			if (motor1.running == 0 && motor2.running == 0 && motor3.running == 0 &&
				motor4.running == 0 && motor5.running == 0 && motor6.running == 0)
			{
				HAL_Delay(100);
				//发送脉冲
				Run_Motors_sync(M1_CLOCKWISE, (Pw_Motor1SendPulse_HW << 16) + Pw_Motor1SendPulse, Pw_Motor1_StartSpeed, Pw_Motor1_SetSpeed, Pw_Motor1_ACCSpeed,
								M2_CLOCKWISE, (Pw_Motor2SendPulse_HW << 16) + Pw_Motor2SendPulse, Pw_Motor2_StartSpeed, Pw_Motor2_SetSpeed, Pw_Motor2_ACCSpeed,
								M3_CLOCKWISE, (Pw_Motor3SendPulse_HW << 16) + Pw_Motor3SendPulse, Pw_Motor3_StartSpeed, Pw_Motor3_SetSpeed, Pw_Motor3_ACCSpeed,
								M4_CLOCKWISE, (Pw_Motor4SendPulse_HW << 16) + Pw_Motor4SendPulse, Pw_Motor4_StartSpeed, Pw_Motor4_SetSpeed, Pw_Motor4_ACCSpeed,
								M5_CLOCKWISE, (Pw_Motor5SendPulse_HW << 16) + Pw_Motor5SendPulse, Pw_Motor5_StartSpeed, Pw_Motor5_SetSpeed, Pw_Motor5_ACCSpeed,
								M6_CLOCKWISE, (Pw_Motor6SendPulse_HW << 16) + Pw_Motor6SendPulse, Pw_Motor6_StartSpeed, Pw_Motor6_SetSpeed, Pw_Motor6_ACCSpeed);

				// Run_Motors_sync(M1_CLOCKWISE, (Pw_Motor1SendPulse_HW << 16) + Pw_Motor1SendPulse, Pw_Motor1_StartSpeed, Pw_Motor1_SetSpeed, Pw_Motor1_ACCSpeed,
				// 				M2_CLOCKWISE, (Pw_Motor2SendPulse_HW << 16) + Pw_Motor2SendPulse, Pw_Motor2_StartSpeed, Pw_Motor2_SetSpeed, Pw_Motor2_ACCSpeed,
				// 				M3_CLOCKWISE, (Pw_Motor3SendPulse_HW << 16) + Pw_Motor3SendPulse, Pw_Motor3_StartSpeed, Pw_Motor3_SetSpeed, Pw_Motor3_ACCSpeed,
				// 				0, 0, 0, 0, 0,
				// 				M5_CLOCKWISE, (Pw_Motor5SendPulse_HW << 16) + Pw_Motor5SendPulse, Pw_Motor5_StartSpeed, Pw_Motor5_SetSpeed, Pw_Motor5_ACCSpeed,
				// 				0, 0, 0, 0, 0);

				// Start_Motor12(M1_CLOCKWISE, 5000, M2_CLOCKWISE, 10000);
				//			Run_Motor_S(1, M1_CLOCKWISE, (Pw_Motor1SendPulse_HW << 16) + Pw_Motor1SendPulse, Pw_Motor1_StartSpeed, Pw_Motor1_SetSpeed, Pw_Motor1_ACCSpeed);
				//			Run_Motor_S(2, M2_CLOCKWISE, (Pw_Motor2SendPulse_HW << 16) + Pw_Motor2SendPulse, Pw_Motor2_StartSpeed, Pw_Motor2_SetSpeed, Pw_Motor2_ACCSpeed);
				//			Run_Motor_S(3, M3_CLOCKWISE, (Pw_Motor3SendPulse_HW << 16) + Pw_Motor3SendPulse, Pw_Motor3_StartSpeed, Pw_Motor3_SetSpeed, Pw_Motor3_ACCSpeed);
				//			Run_Motor_S(4, M4_CLOCKWISE, (Pw_Motor4SendPulse_HW << 16) + Pw_Motor4SendPulse, Pw_Motor4_StartSpeed, Pw_Motor4_SetSpeed, Pw_Motor4_ACCSpeed);
				//			Run_Motor_S(5, M5_CLOCKWISE, (Pw_Motor5SendPulse_HW << 16) + Pw_Motor5SendPulse, Pw_Motor5_StartSpeed, Pw_Motor5_SetSpeed, Pw_Motor5_ACCSpeed);
				//			Run_Motor_S(6, M6_CLOCKWISE, (Pw_Motor6SendPulse_HW << 16) + Pw_Motor6SendPulse, Pw_Motor6_StartSpeed, Pw_Motor6_SetSpeed, Pw_Motor6_ACCSpeed);
			}
		}
	}
	Old_K_SecondPonit = K_SecondPonit;
}

//初始化电机的PWM
void Initial_PWM_Motors(void)
{
	Initial_PWM_Motor1(); //初始化电机1的PWM
	Initial_PWM_Motor2(); //初始化电机2的PWM
	Initial_PWM_Motor3(); //初始化电机3的PWM
	Initial_PWM_Motor4(); //初始化电机4的PWM
	Initial_PWM_Motor5(); //初始化电机5的PWM
	Initial_PWM_Motor6(); //初始化电机6的PWM
}

//读写EtherCAT的IO口
void Rd2Wr_IO(void)
{
	CMD13_IORD(1);
	SPI_exchange_polling();

	HAL_Delay(100);
	// for (i = 1; i < DEF_MA_MAX - 1; i++) //读取IO输入状态
	// {
	if (bNetworkMap[0] == IO)
	{
		IO_Input = rbuff[1].Data1;
#ifndef Printf_ON
		printf("IO_Input =%x\n\r", IO_Input);
#endif
	}
	// }

	/*控制子站IO输出*/
	//		for(i=1;i< DEF_MA_MAX-1;i++){
	//						CMD14_IOWR(i,0x55555555);
	CMD14_IOWR(1, IO_Input);
	//			CMD14_IOWR(i,IO_Input);
	//		}
	SPI_exchange_polling();

	HAL_Delay(100);
	CMD00_GET_STATUS(1);
	SPI_exchange_polling();
}

int userGetchar(void)
{
	uint8_t charbuf;
	HAL_StatusTypeDef ret;
	ret = HAL_UART_Receive(&huart3, &charbuf, 1, 0xffffffff);
	if (ret)
		return -ret;
	return charbuf;
}

/* USER CODE END 4 */

void Error_Handler(void)
{
	__disable_irq();
	while (1)
	{
	}
}

/************************ (C) COPYRIGHT STMicroelectronics *****END OF FILE****/
